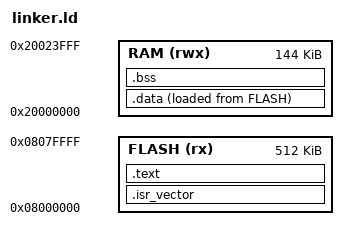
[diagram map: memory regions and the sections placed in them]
ENTRY(Reset_Handler)

MEMORY
{
  FLASH (rx) : ORIGIN = 0x08000000, LENGTH = 512K
  RAM (rwx)  : ORIGIN = 0x20000000, LENGTH = 144K
}

_estack = ORIGIN(RAM) + LENGTH(RAM);

_sidata = LOADADDR(.data);
_sdata = .;
_edata = .;
_sbss = .;
_ebss = .;


SECTIONS
{
  .isr_vector : {
    . = ALIGN(4);
    KEEP(*(.isr_vector))
  } > FLASH

  .text : {
    . = ALIGN(4);
    *(.text*)
    *(.rodata*)
    . = ALIGN(4);
    _etext = .;  
  } > FLASH

  .data : {
    . = ALIGN(4);
    _sdata = .;
    _sidata = LOADADDR(.data);
    *(.data*)
    . = ALIGN(4);
    _edata = .;
  } > RAM AT > FLASH

  .bss : {
    _sbss = .;
    . = ALIGN(4);
    *(.bss*)
    *(COMMON)
    . = ALIGN(4);
    _ebss = .;
  } > RAM
}
